NS_ :

BS_:

BU_: XXX DSU HCU EPS IPAS CGW

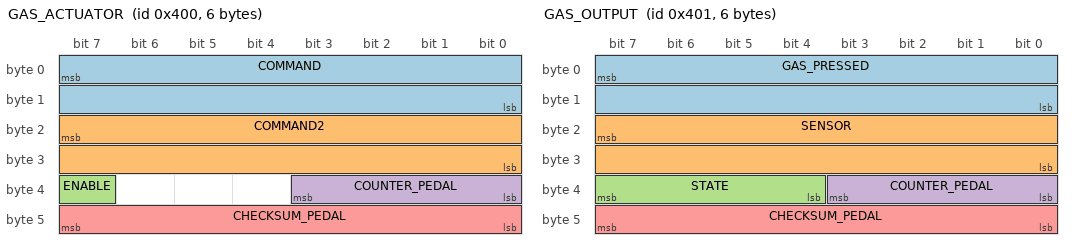
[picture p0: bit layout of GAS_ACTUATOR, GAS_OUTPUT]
BO_ 1024 GAS_ACTUATOR: 6 EON
 SG_ COMMAND : 7|16@0+ (0.882353,-2888.8235) [0|1] "" INTERCEPTOR
 SG_ COMMAND2 : 23|16@0+ (0.882353,-2888.8235) [0|1] "" INTERCEPTOR
 SG_ ENABLE : 39|1@0+ (1,0) [0|1] "" INTERCEPTOR
 SG_ COUNTER_PEDAL : 35|4@0+ (1,0) [0|15] "" INTERCEPTOR
 SG_ CHECKSUM_PEDAL : 47|8@0+ (1,0) [0|255] "" INTERCEPTOR

BO_ 1025 GAS_OUTPUT: 6 INTERCEPTOR
 SG_ GAS_PRESSED : 7|16@0+ (0.882353,-50) [0|1] "" EON
 SG_ SENSOR : 23|16@0+ (0.882353,-2888.8235) [0|1] "" EON
 SG_ STATE : 39|4@0+ (1,0) [0|15] "" EON
 SG_ COUNTER_PEDAL : 35|4@0+ (1,0) [0|15] "" EON
 SG_ CHECKSUM_PEDAL : 47|8@0+ (1,0) [0|255] "" EON

VAL_ 1025 STATE 5 "FAULT_TIMEOUT" 4 "FAULT_STARTUP" 3 "FAULT_SCE" 2 "FAULT_SEND" 1 "FAULT_BAD_CHECKSUM" 0 "NO_FAULT" ;

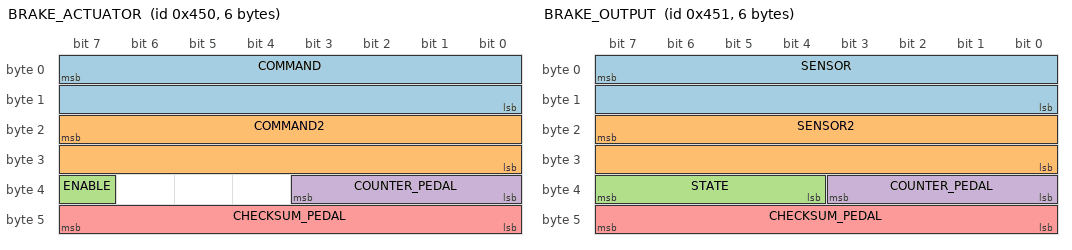
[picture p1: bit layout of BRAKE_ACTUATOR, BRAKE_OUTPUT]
BO_ 1104 BRAKE_ACTUATOR: 6 EON
 SG_ COMMAND : 7|16@0+ (0.08242,0) [0|1] "" INTERCEPTOR
 SG_ COMMAND2 : 23|16@0+ (0.08242,0) [0|1] "" INTERCEPTOR
 SG_ ENABLE : 39|1@0+ (1,0) [0|1] "" INTERCEPTOR
 SG_ COUNTER_PEDAL : 35|4@0+ (1,0) [0|15] "" INTERCEPTOR
 SG_ CHECKSUM_PEDAL : 47|8@0+ (1,0) [0|255] "" INTERCEPTOR

BO_ 1105 BRAKE_OUTPUT: 6 INTERCEPTOR
 SG_ SENSOR : 7|16@0+ (0.882353,-2888.8235) [0|1] "" EON
 SG_ SENSOR2 : 23|16@0+ (0.882353,-2888.8235) [0|1] "" EON
 SG_ STATE : 39|4@0+ (1,0) [0|15] "" EON
 SG_ COUNTER_PEDAL : 35|4@0+ (1,0) [0|15] "" EON
 SG_ CHECKSUM_PEDAL : 47|8@0+ (1,0) [0|255] "" EON

VAL_ 1105 STATE 5 "FAULT_TIMEOUT" 4 "FAULT_STARTUP" 3 "FAULT_SCE" 2 "FAULT_SEND" 1 "FAULT_BAD_CHECKSUM" 0 "NO_FAULT" ;

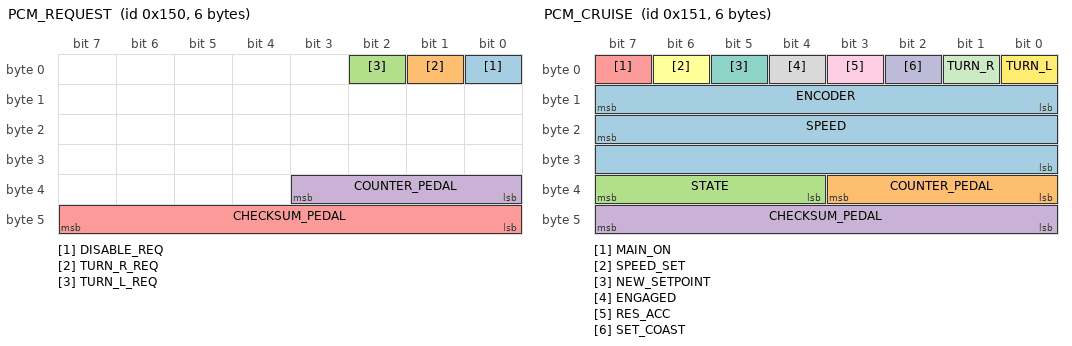
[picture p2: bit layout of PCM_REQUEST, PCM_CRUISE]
BO_ 336 PCM_REQUEST: 6 EON
 SG_ DISABLE_REQ : 0|1@0+ (1,0) [0|1] "" INTERCEPTOR
 SG_ TURN_R_REQ : 1|1@0+ (1,0) [0|1] "" INTERCEPTOR
 SG_ TURN_L_REQ : 2|1@0+ (1,0) [0|1] "" INTERCEPTOR
 SG_ COUNTER_PEDAL : 35|4@0+ (1,0) [0|15] "" INTERCEPTOR
 SG_ CHECKSUM_PEDAL : 47|8@0+ (1,0) [0|255] "" INTERCEPTOR

BO_ 337 PCM_CRUISE: 6 XXX
 SG_ ENCODER : 15|8@0+ (1,0) [0|255] "" XXX
 SG_ COUNTER_PEDAL : 32|4@1+ (1,0) [0|15] "" XXX
 SG_ STATE : 39|4@0+ (1,0) [0|15] "" XXX
 SG_ CHECKSUM_PEDAL : 47|8@0+ (1,0) [0|255] "" XXX
 SG_ MAIN_ON : 7|1@0+ (1,0) [0|1] "" XXX
 SG_ SPEED_SET : 6|1@0+ (1,0) [0|1] "" XXX
 SG_ NEW_SETPOINT : 5|1@0+ (1,0) [0|1] "" XXX
 SG_ ENGAGED : 4|1@0+ (1,0) [0|1] "" XXX
 SG_ RES_ACC : 3|1@0+ (1,0) [0|1] "" XXX
 SG_ SET_COAST : 2|1@0+ (1,0) [0|1] "" XXX
 SG_ TURN_R : 1|1@0+ (1,0) [0|1] "" XXX
 SG_ TURN_L : 0|1@0+ (1,0) [0|1] "" XXX
 SG_ SPEED : 23|16@0+ (0.175,0) [0|65535] "km/h" XXX

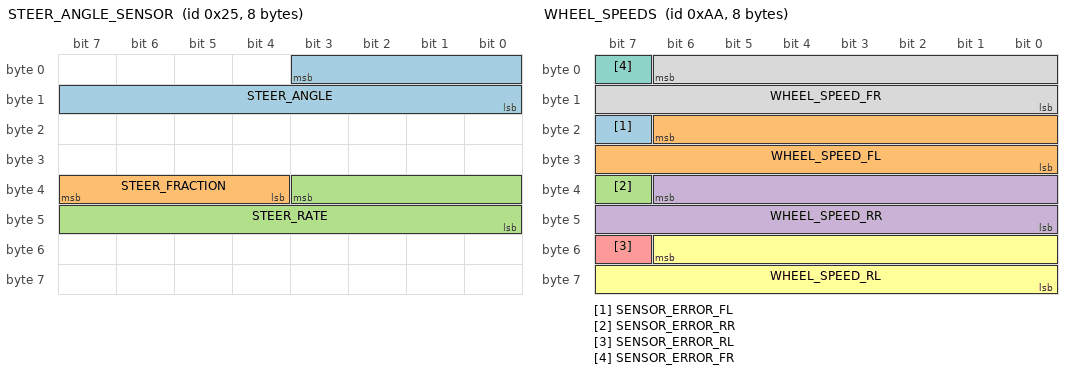
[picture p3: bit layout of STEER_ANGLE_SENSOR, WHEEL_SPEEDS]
BO_ 37 STEER_ANGLE_SENSOR: 8 XXX
 SG_ STEER_ANGLE : 3|12@0- (1.5,132) [-500|500] "deg" XXX
 SG_ STEER_FRACTION : 39|4@0- (0.1,0) [-0.7|0.7] "deg" XXX
 SG_ STEER_RATE : 35|12@0- (1,0) [-2000|2000] "deg/s" XXX

BO_ 170 WHEEL_SPEEDS: 8 XXX
 SG_ SENSOR_ERROR_FL : 23|1@0+ (1,0) [0|1] "" XXX
 SG_ WHEEL_SPEED_FL : 22|15@0+ (0.01,-67.67) [0|250] "kph" XXX
 SG_ SENSOR_ERROR_RR : 39|1@0+ (1,0) [0|1] "" XXX
 SG_ WHEEL_SPEED_RR : 38|15@0+ (0.01,-67.67) [0|250] "kph" XXX
 SG_ SENSOR_ERROR_RL : 55|1@0+ (1,0) [0|1] "" XXX
 SG_ WHEEL_SPEED_RL : 54|15@0+ (0.01,-67.67) [0|250] "kph" XXX
 SG_ SENSOR_ERROR_FR : 7|1@0+ (1,0) [0|1] "" XXX
 SG_ WHEEL_SPEED_FR : 6|15@0+ (0.01,-67.67) [0|250] "kph" XXX

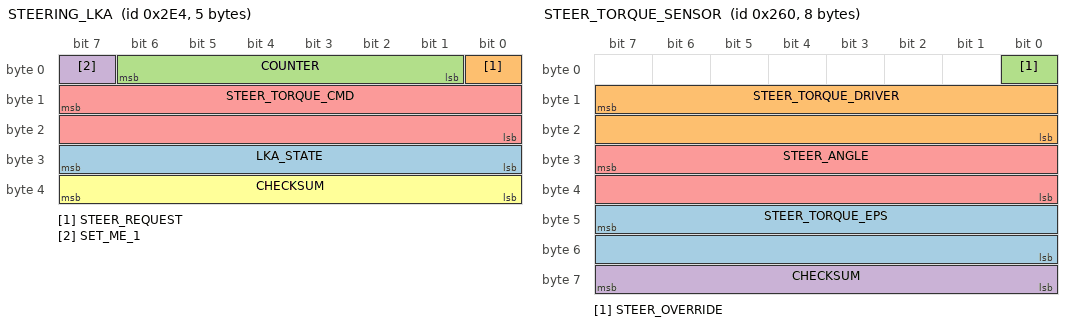
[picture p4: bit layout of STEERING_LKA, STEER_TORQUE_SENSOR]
BO_ 740 STEERING_LKA: 5 XXX
 SG_ LKA_STATE : 31|8@0+ (1,0) [0|255] "" XXX
 SG_ STEER_REQUEST : 0|1@0+ (1,0) [0|1] "" XXX
 SG_ COUNTER : 6|6@0+ (1,0) [0|63] "" XXX
 SG_ SET_ME_1 : 7|1@0+ (1,0) [0|1] "" XXX
 SG_ STEER_TORQUE_CMD : 15|16@0- (1,0) [0|65535] "" XXX
 SG_ CHECKSUM : 39|8@0+ (1,0) [0|255] "" XXX

BO_ 548 BRAKE_MODULE: 8 XXX
 SG_ BRAKE_PRESSURE : 35|12@0+ (1,0) [0|4047] "" XXX

BO_ 608 STEER_TORQUE_SENSOR: 8 XXX
 SG_ STEER_TORQUE_EPS : 47|16@0- (1.0,0) [-20000|20000] "" XXX
 SG_ STEER_TORQUE_DRIVER : 15|16@0- (1,0) [-32768|32767] "" XXX
 SG_ STEER_OVERRIDE : 0|1@0+ (1,0) [0|1] "" XXX
 SG_ CHECKSUM : 63|8@0+ (1,0) [0|255] "" XXX
 SG_ STEER_ANGLE : 31|16@0- (0.0573,0) [-500|500] "" XXX

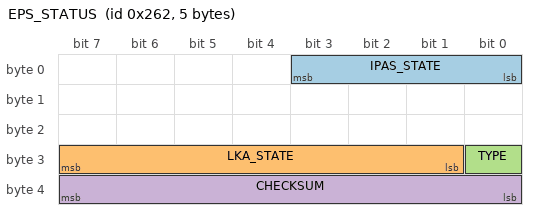
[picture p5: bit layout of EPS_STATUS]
BO_ 610 EPS_STATUS: 5 EPS
 SG_ IPAS_STATE : 3|4@0+ (1,0) [0|15] "" XXX
 SG_ LKA_STATE : 31|7@0+ (1,0) [0|127] "" XXX
 SG_ TYPE : 24|1@0+ (1,0) [0|1] "" XXX
 SG_ CHECKSUM : 39|8@0+ (1,0) [0|255] "" XXX

BO_ 956 GEAR_PACKET: 8 XXX
 SG_ GEAR : 13|6@0+ (1,0) [0|63] "" XXX
 SG_ SPORT_ON : 3|1@0+ (1,0) [0|1] "" XXX

CM_ SG_ 548 BRAKE_PRESSURE "seems prop to pedal force";
CM_ SG_ 548 BRAKE_POSITION "seems proportional to pedal displacement, unclear the max value of 0x1c8";
CM_ SG_ 610 TYPE "seems 1 on Corolla, 0 on all others";
VAL_ 610 IPAS_STATE 5 "override" 3 "enabled" 1 "disabled";
VAL_ 610 LKA_STATE 25 "temporary_fault" 9 "temporary_fault2" 5 "active" 1 "standby";
VAL_ 956 GEAR 0 "D" 1 "S" 8 "N" 16 "R" 32 "P";
